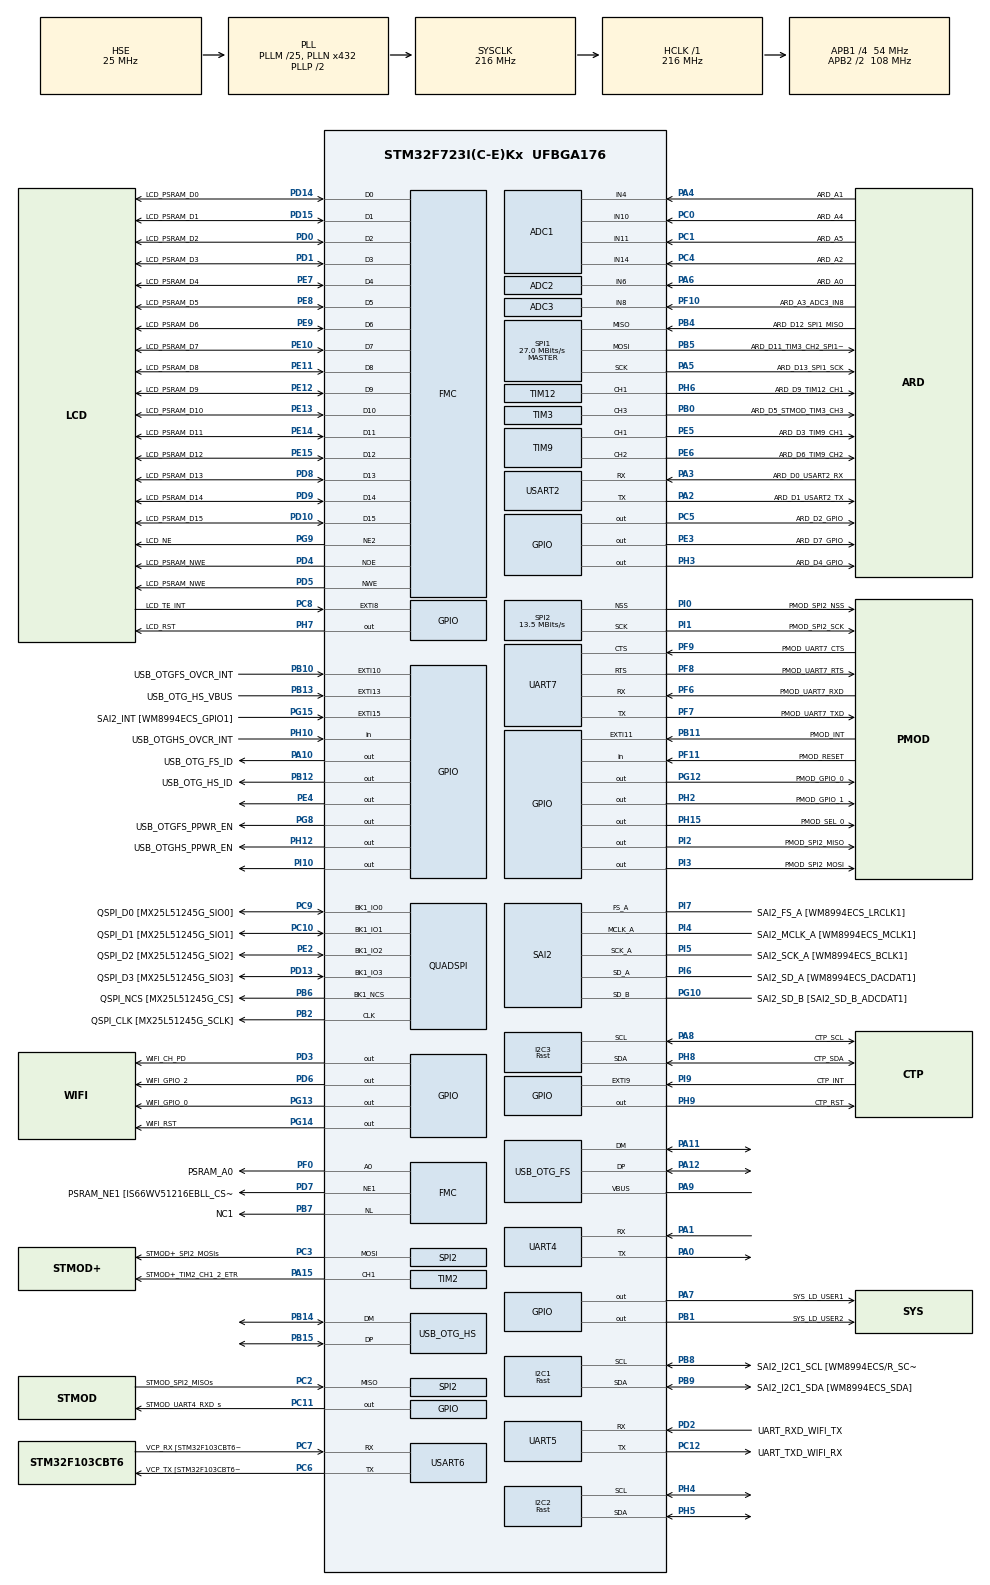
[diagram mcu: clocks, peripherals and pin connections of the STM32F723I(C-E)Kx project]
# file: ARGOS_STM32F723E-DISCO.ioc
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ADC1.Channel-0\#ChannelRegularConversion=ADC_CHANNEL_6
ADC1.Channel-11\#ChannelRegularConversion=ADC_CHANNEL_14
ADC1.Channel-8\#ChannelRegularConversion=ADC_CHANNEL_4
ADC1.ContinuousConvMode=ENABLE
ADC1.DiscontinuousConvMode=DISABLE
ADC1.EOCSelection=ADC_EOC_SINGLE_CONV
ADC1.ExternalTrigConv=ADC_SOFTWARE_START
ADC1.NbrOfConversion=3
ADC1.NbrOfConversionFlag=1
ADC1.Rank-0\#ChannelRegularConversion=1
ADC1.Rank-11\#ChannelRegularConversion=3
ADC1.Rank-8\#ChannelRegularConversion=2
ADC1.SamplingTime-0\#ChannelRegularConversion=ADC_SAMPLETIME_480CYCLES
ADC1.SamplingTime-11\#ChannelRegularConversion=ADC_SAMPLETIME_480CYCLES
ADC1.SamplingTime-8\#ChannelRegularConversion=ADC_SAMPLETIME_480CYCLES
ADC1.master=1
ADC2.Channel-25\#ChannelRegularConversion=ADC_CHANNEL_4
ADC2.NbrOfConversionFlag=1
ADC2.Rank-25\#ChannelRegularConversion=1
ADC2.SamplingTime-25\#ChannelRegularConversion=ADC_SAMPLETIME_3CYCLES
ADC3.Channel-0\#ChannelRegularConversion=ADC_CHANNEL_8
ADC3.NbrOfConversionFlag=1
ADC3.Rank-0\#ChannelRegularConversion=1
ADC3.SamplingTime-0\#ChannelRegularConversion=ADC_SAMPLETIME_3CYCLES
CORTEX_M7.CPU_ICache=Disabled
CORTEX_M7.PREFETCH_ENABLE=0
FMC.WriteOperation1=FMC_WRITE_OPERATION_ENABLE
I2C1.I2C_Speed_Mode=I2C_Fast
I2C1.Timing=0x6000030D
I2C2.I2C_Speed_Mode=I2C_Fast
I2C2.Timing=0x6000030D
I2C3.I2C_Speed_Mode=I2C_Fast
I2C3.Speed=400
I2C3.Timing=0x6000030D
Mcu.Family=STM32F7
Mcu.Name=STM32F723I(C-E)Kx
Mcu.Package=UFBGA176
NVIC.ADC_IRQn=true\:0\:0\:false\:false\:true\:true\:true\:true
NVIC.OTG_FS_IRQn=true\:0\:0\:false\:false\:true\:true\:true\:true
NVIC.OTG_HS_IRQn=true\:0\:0\:false\:false\:true\:true\:true\:true
NVIC.PriorityGroup=NVIC_PRIORITYGROUP_4
NVIC.TIM1_UP_TIM10_IRQn=true\:15\:0\:false\:false\:true\:true\:true\:true
NVIC.TIM5_IRQn=true\:0\:0\:false\:false\:true\:true\:true\:true
NVIC.TimeBase=TIM1_UP_TIM10_IRQn
NVIC.TimeBaseIP=TIM1
PA0-WKUP.GPIO_ModeDefaultPP=GPIO_MODE_AF_PP
PA0-WKUP.GPIO_PuPd=GPIO_NOPULL
PA0-WKUP.GPIO_Speed=GPIO_SPEED_FREQ_VERY_HIGH
PA0-WKUP.Mode=Asynchronous
PA0-WKUP.Signal=UART4_TX
PA1.Mode=Asynchronous
PA1.Signal=UART4_RX
PA10.GPIO_Label=USB_OTG_FS_ID
PA10.Signal=GPIO_Output
PA11.Mode=Host_Only
PA11.Signal=USB_OTG_FS_DM
PA12.Mode=Host_Only
PA12.Signal=USB_OTG_FS_DP
PA13.Mode=Trace_Asynchronous_SW
PA13.Signal=SYS_JTMS-SWDIO
PA14.Mode=Trace_Asynchronous_SW
PA14.Signal=SYS_JTCK-SWCLK
PA15.GPIO_Label=STMOD+_TIM2_CH1_2_ETR
PA15.Signal=S_TIM2_CH1_ETR
PA2.GPIO_Label=ARD_D1_USART2_TX
PA2.Mode=Asynchronous
PA2.Signal=USART2_TX
PA3.GPIO_Label=ARD_D0_USART2_RX
PA3.Mode=Asynchronous
PA3.Signal=USART2_RX
PA4.GPIO_Label=ARD_A1
PA4.Signal=ADCx_IN4
PA5.GPIO_Label=ARD_D13_SPI1_SCK
PA5.Mode=Full_Duplex_Master
PA5.Signal=SPI1_SCK
PA6.GPIO_Label=ARD_A0
PA6.Signal=ADCx_IN6
PA7.GPIO_Label=SYS_LD_USER1
PA7.Signal=GPIO_Output
PA8.GPIO_Label=CTP_SCL
PA8.GPIO_Pu=GPIO_PULLUP
PA8.Mode=I2C
PA8.Signal=I2C3_SCL
PA9.Mode=Activate_VBUS
PA9.Signal=USB_OTG_FS_VBUS
PB0.GPIO_Label=ARD_D5_STMOD_TIM3_CH3
PB0.Signal=S_TIM3_CH3
PB1.GPIO_Label=SYS_LD_USER2
PB1.Signal=GPIO_Output
PB10.GPIO_Label=USB_OTGFS_OVCR_INT
PB10.Signal=GPXTI10
PB11.GPIO_Label=PMOD_INT
PB11.Signal=GPXTI11
PB12.GPIO_Label=USB_OTG_HS_ID
PB12.Signal=GPIO_Output
PB13.GPIO_Label=USB_OTG_HS_VBUS
PB13.Signal=GPXTI13
PB14.Mode=Internal_Phy_Host
PB14.Signal=USB_OTG_HS_DM
PB15.Mode=Internal_Phy_Host
PB15.Signal=USB_OTG_HS_DP
PB2.GPIO_Label=QSPI_CLK [MX25L51245G_SCLK]
PB2.Mode=Single Bank 1
PB2.Signal=QUADSPI_CLK
PB3.GPIO_Label=SYS_STLINK_JTDO_SWO
PB3.Mode=Trace_Asynchronous_SW
PB3.Signal=SYS_JTDO-SWO
PB4.GPIO_Label=ARD_D12_SPI1_MISO
PB4.Mode=Full_Duplex_Master
PB4.Signal=SPI1_MISO
PB5.GPIO_Label=ARD_D11_TIM3_CH2_SPI1_MOSI
PB5.Mode=Full_Duplex_Master
PB5.Signal=SPI1_MOSI
PB6.GPIO_Label=QSPI_NCS [MX25L51245G_CS]
PB6.Mode=Single Bank 1
PB6.Signal=QUADSPI_BK1_NCS
PB7.GPIO_Label=NC1
PB7.Signal=FMC_NL
PB8.GPIO_Label=SAI2_I2C1_SCL [WM8994ECS/R_SCLK]
PB8.GPIO_Pu=GPIO_PULLUP
PB8.Mode=I2C
PB8.Signal=I2C1_SCL
PB9.GPIO_Label=SAI2_I2C1_SDA [WM8994ECS_SDA]
PB9.GPIO_Pu=GPIO_PULLUP
PB9.Mode=I2C
PB9.Signal=I2C1_SDA
PC0.GPIO_Label=ARD_A4
PC0.Signal=ADCx_IN10
PC1.GPIO_Label=ARD_A5
PC1.Signal=ADCx_IN11
PC10.GPIO_Label=QSPI_D1 [MX25L51245G_SIO1]
PC10.Mode=Single Bank 1
PC10.Signal=QUADSPI_BK1_IO1
PC11.GPIO_Label=STMOD_UART4_RXD_s
PC11.Signal=GPIO_Output
PC12.GPIO_Label=UART_TXD_WIFI_RX
PC12.Mode=Asynchronous
PC12.Signal=UART5_TX
PC14-OSC32_IN.Mode=LSE-External-Oscillator
PC14-OSC32_IN.Signal=RCC_OSC32_IN
PC15-OSC32_OUT.Mode=LSE-External-Oscillator
PC15-OSC32_OUT.Signal=RCC_OSC32_OUT
PC2.GPIO_Label=STMOD_SPI2_MISOs
PC2.Mode=Full_Duplex_Master
PC2.Signal=SPI2_MISO
PC3.GPIO_Label=STMOD+_SPI2_MOSIs
PC3.Mode=Full_Duplex_Master
PC3.Signal=SPI2_MOSI
PC4.GPIO_Label=ARD_A2
PC4.Signal=ADCx_IN14
PC5.GPIO_Label=ARD_D2_GPIO
PC5.Signal=GPIO_Output
PC6.GPIO_Label=VCP_TX [STM32F103CBT6_PA3]
PC6.Mode=Asynchronous
PC6.Signal=USART6_TX
PC7.GPIO_Label=VCP_RX [STM32F103CBT6_PA2]
PC7.Mode=Asynchronous
PC7.Signal=USART6_RX
PC8.GPIO_Label=LCD_TE_INT
PC8.Signal=GPXTI8
PC9.GPIO_Label=QSPI_D0 [MX25L51245G_SIO0]
PC9.Mode=Single Bank 1
PC9.Signal=QUADSPI_BK1_IO0
PD0.GPIO_Label=LCD_PSRAM_D2
PD0.Signal=FMC_D2_DA2
PD1.GPIO_Label=LCD_PSRAM_D3
PD1.Signal=FMC_D3_DA3
PD10.GPIO_Label=LCD_PSRAM_D15
PD10.Signal=FMC_D15_DA15
PD11.GPIO_Label=PSRAM_A16
PD11.Signal=FMC_A16_CLE
PD12.GPIO_Label=PSRAM_A17
PD12.Signal=FMC_A17_ALE
PD13.GPIO_Label=QSPI_D3 [MX25L51245G_SIO3]
PD13.Mode=Single Bank 1
PD13.Signal=QUADSPI_BK1_IO3
PD14.GPIO_Label=LCD_PSRAM_D0
PD14.Signal=FMC_D0_DA0
PD15.GPIO_Label=LCD_PSRAM_D1
PD15.Signal=FMC_D1_DA1
PD2.GPIO_Label=UART_RXD_WIFI_TX
PD2.Mode=Asynchronous
PD2.Signal=UART5_RX
PD3.GPIO_Label=WIFI_CH_PD
PD3.Signal=GPIO_Output
PD4.GPIO_Label=LCD_PSRAM_NWE
PD4.Signal=FMC_NOE
PD5.GPIO_Label=LCD_PSRAM_NWE
PD5.Signal=FMC_NWE
PD6.GPIO_Label=WIFI_GPIO_2
PD6.Signal=GPIO_Output
PD7.GPIO_Label=PSRAM_NE1 [IS66WV51216EBLL_CS1]
PD7.Mode=NorPsramChipSelect1_1
PD7.Signal=FMC_NE1
PD8.GPIO_Label=LCD_PSRAM_D13
PD8.Signal=FMC_D13_DA13
PD9.GPIO_Label=LCD_PSRAM_D14
PD9.Signal=FMC_D14_DA14
PE0.GPIO_Label=PSRAM_NBL0 [IS66WV51216EBLL_LB]
PE0.Signal=FMC_NBL0
PE1.GPIO_Label=PSRAM_NBL1 [IS66WV51216EBLL_UB]
PE1.Signal=FMC_NBL1
PE10.GPIO_Label=LCD_PSRAM_D7
PE10.Signal=FMC_D7_DA7
PE11.GPIO_Label=LCD_PSRAM_D8
PE11.Signal=FMC_D8_DA8
PE12.GPIO_Label=LCD_PSRAM_D9
PE12.Signal=FMC_D9_DA9
PE13.GPIO_Label=LCD_PSRAM_D10
PE13.Signal=FMC_D10_DA10
PE14.GPIO_Label=LCD_PSRAM_D11
PE14.Signal=FMC_D11_DA11
PE15.GPIO_Label=LCD_PSRAM_D12
PE15.Signal=FMC_D12_DA12
PE2.GPIO_Label=QSPI_D2 [MX25L51245G_SIO2]
PE2.Mode=Single Bank 1
PE2.Signal=QUADSPI_BK1_IO2
PE3.GPIO_Label=ARD_D7_GPIO
PE3.Signal=GPIO_Output
PE4.Signal=GPIO_Output
PE5.GPIO_Label=ARD_D3_TIM9_CH1
PE5.Signal=S_TIM9_CH1
PE6.GPIO_Label=ARD_D6_TIM9_CH2
PE6.Signal=S_TIM9_CH2
PE7.GPIO_Label=LCD_PSRAM_D4
PE7.Signal=FMC_D4_DA4
PE8.GPIO_Label=LCD_PSRAM_D5
PE8.Signal=FMC_D5_DA5
PE9.GPIO_Label=LCD_PSRAM_D6
PE9.Signal=FMC_D6_DA6
PF0.GPIO_Label=PSRAM_A0
PF0.Signal=FMC_A0
PF10.GPIO_Label=ARD_A3_ADC3_IN8
PF10.Mode=IN8
PF10.Signal=ADC3_IN8
PF11.GPIO_Label=PMOD_RESET
PF11.Signal=GPIO_Input
PF12.GPIO_Label=PSRAM_A6
PF12.Signal=FMC_A6
PF13.GPIO_Label=PSRAM_A7
PF13.Signal=FMC_A7
PF14.GPIO_Label=PSRAM_A8
PF14.Signal=FMC_A8
PF15.GPIO_Label=PSRAM_A9
PF15.Signal=FMC_A9
PF2.GPIO_Label=PSRAM_A2
PF2.Signal=FMC_A2
PF3.GPIO_Label=PSRAM_A3
PF3.Signal=FMC_A3
PF4.GPIO_Label=PSRAM_A4
PF4.Signal=FMC_A4
PF5.GPIO_Label=PSRAM_A5
PF5.Signal=FMC_A5
PF6.GPIO_Label=PMOD_UART7_RXD
PF6.Mode=Asynchronous
PF6.Signal=UART7_RX
PF7.GPIO_Label=PMOD_UART7_TXD
PF7.Mode=Asynchronous
PF7.Signal=UART7_TX
PF8.GPIO_Label=PMOD_UART7_RTS
PF8.Mode=CTS_RTS
PF8.Signal=UART7_RTS
PF9.GPIO_Label=PMOD_UART7_CTS
PF9.Mode=CTS_RTS
PF9.Signal=UART7_CTS
PG0.GPIO_Label=PSRAM_A10
PG0.Signal=FMC_A10
PG1.GPIO_Label=PSRAM_A11
PG1.Signal=FMC_A11
PG10.GPIO_Label=SAI2_SD_B [SAI2_SD_B_ADCDAT1]
PG10.Mode=SAI_B_SyncSlave
PG10.Signal=SAI2_SD_B
PG12.GPIO_Label=PMOD_GPIO_0
PG12.Signal=GPIO_Output
PG13.GPIO_Label=WIFI_GPIO_0
PG13.Signal=GPIO_Output
PG14.GPIO_Label=WIFI_RST
PG14.Signal=GPIO_Output
PG15.GPIO_Label=SAI2_INT [WM8994ECS_GPIO1]
PG15.Signal=GPXTI15
PG2.GPIO_Label=PSRAM_A12
PG2.Signal=FMC_A12
PG3.GPIO_Label=PSRAM_A13
PG3.Signal=FMC_A13
PG4.GPIO_Label=PSRAM_A14
PG4.Signal=FMC_A14_BA0
PG5.GPIO_Label=PSRAM_A15
PG5.Signal=FMC_A15_BA1
PG8.GPIO_Label=USB_OTGFS_PPWR_EN
PG8.Signal=GPIO_Output
PG9.GPIO_Label=LCD_NE
PG9.Mode=NorPsramChipSelect2_2
PG9.Signal=FMC_NE2
PH0-OSC_IN.Mode=HSE-External-Oscillator
PH0-OSC_IN.Signal=RCC_OSC_IN
PH1-OSC_OUT.Mode=HSE-External-Oscillator
PH1-OSC_OUT.Signal=RCC_OSC_OUT
PH10.GPIO_Label=USB_OTGHS_OVCR_INT
PH10.Signal=GPIO_Input
PH11.GPIO_Label=LCD_BL [STLD40DPUR_EN]
PH11.Signal=S_TIM5_CH2
PH12.GPIO_Label=USB_OTGHS_PPWR_EN
PH12.Signal=GPIO_Output
PH15.GPIO_Label=PMOD_SEL_0
PH15.PinState=GPIO_PIN_SET
PH15.Signal=GPIO_Output
PH2.GPIO_Label=PMOD_GPIO_1
PH2.Signal=GPIO_Output
PH3.GPIO_Label=ARD_D4_GPIO
PH3.Signal=GPIO_Output
PH4.Mode=I2C
PH4.Signal=I2C2_SCL
PH5.Mode=I2C
PH5.Signal=I2C2_SDA
PH6.GPIO_Label=ARD_D9_TIM12_CH1
PH6.Signal=S_TIM12_CH1
PH7.GPIO_Label=LCD_RST
PH7.Signal=GPIO_Output
PH8.GPIO_Label=CTP_SDA
PH8.GPIO_Pu=GPIO_PULLUP
PH8.Mode=I2C
PH8.Signal=I2C3_SDA
PH9.GPIO_Label=CTP_RST
PH9.Signal=GPIO_Output
PI0.GPIO_Label=PMOD_SPI2_NSS
PI0.Mode=NSS_Signal_Hard_Output
PI0.Signal=SPI2_NSS
PI1.GPIO_Label=PMOD_SPI2_SCK
PI1.Mode=Full_Duplex_Master
PI1.Signal=SPI2_SCK
PI10.Signal=GPIO_Output
PI2.GPIO_Label=PMOD_SPI2_MISO
PI2.Signal=GPIO_Output
PI3.GPIO_Label=PMOD_SPI2_MOSI
PI3.Signal=GPIO_Output
PI4.GPIO_Label=SAI2_MCLK_A [WM8994ECS_MCLK1]
PI4.Mode=SAI_A_MasterWithClock
PI4.Signal=SAI2_MCLK_A
PI5.GPIO_Label=SAI2_SCK_A [WM8994ECS_BCLK1]
PI5.Mode=SAI_A_MasterWithClock
PI5.Signal=SAI2_SCK_A
PI6.GPIO_Label=SAI2_SD_A [WM8994ECS_DACDAT1]
PI6.Mode=SAI_A_MasterWithClock
PI6.Signal=SAI2_SD_A
PI7.GPIO_Label=SAI2_FS_A [WM8994ECS_LRCLK1]
PI7.Mode=SAI_A_MasterWithClock
PI7.Signal=SAI2_FS_A
PI9.GPIO_Label=CTP_INT
PI9.Signal=GPXTI9
ProjectManager.HeapSize=0x200
ProjectManager.StackSize=0x400
ProjectManager.TargetToolchain=Makefile
QUADSPI.ChipSelectHighTime=QSPI_CS_HIGH_TIME_4_CYCLE
QUADSPI.ClockPrescaler=1
QUADSPI.FifoThreshold=16
QUADSPI.FlashSize=26
QUADSPI.SampleShifting=QSPI_SAMPLE_SHIFTING_HALFCYCLE
RCC.AHBFreq_Value=216000000
RCC.APB1CLKDivider=RCC_HCLK_DIV4
RCC.APB1Freq_Value=54000000
RCC.APB1TimFreq_Value=108000000
RCC.APB2CLKDivider=RCC_HCLK_DIV2
RCC.APB2Freq_Value=108000000
RCC.APB2TimFreq_Value=216000000
RCC.CortexFreq_Value=216000000
RCC.HCLKFreq_Value=216000000
RCC.HSE_VALUE=25000000
RCC.HSI_VALUE=16000000
RCC.PLLM=25
RCC.PLLN=432
RCC.PLLQ=9
RCC.SYSCLKFreq_VALUE=216000000
RCC.SYSCLKSource=RCC_SYSCLKSOURCE_PLLCLK
RCC.USBFreq_Value=48000000
RCC.VCOOutputFreq_Value=432000000
REXTPHYHS.GPIO_Label=REXT_OTGPHY
REXTPHYHS.Mode=Internal_Phy_Host
REXTPHYHS.Signal=USB_OTG_HS_REXTPHYHS
SAI2.ErrorAudioFreq-SAI_A_MasterWithClock=-2.34 %
SAI2.Instance-SAI_A_MasterWithClock=SAI$Index_Block_A
SAI2.Instance-SAI_B_SyncSlave=SAI$Index_Block_B
SAI2.MClockEnable-SAI_A_MasterWithClock=SAI_MASTERCLOCK_ENABLE
SAI2.RealAudioFreq-SAI_A_MasterWithClock=187.5 KHz
SAI2.VirtualMode-SAI_A_MasterWithClock=VM_MASTER
SAI2.VirtualMode-SAI_B_SyncSlave=VM_SLAVE
SH.ADCx_IN10.0=ADC1_IN10,IN10
SH.ADCx_IN10.1=ADC2_IN10,IN10
SH.ADCx_IN11.0=ADC1_IN11,IN11
SH.ADCx_IN11.1=ADC2_IN11,IN11
SH.ADCx_IN14.0=ADC1_IN14,IN14
SH.ADCx_IN14.1=ADC2_IN14,IN14
SH.ADCx_IN4.0=ADC1_IN4,IN4
SH.ADCx_IN4.1=ADC2_IN4,IN4
SH.ADCx_IN6.0=ADC2_IN6,IN6
SH.ADCx_IN6.1=ADC1_IN6,IN6
SH.FMC_A0.0=FMC_A0,A0_2
SH.FMC_A10.0=FMC_A10
SH.FMC_A11.0=FMC_A11
SH.FMC_A12.0=FMC_A12
SH.FMC_A13.0=FMC_A13
SH.FMC_A14_BA0.0=FMC_A14
SH.FMC_A15_BA1.0=FMC_A15
SH.FMC_A16_CLE.0=FMC_A16
SH.FMC_A17_ALE.0=FMC_A17
SH.FMC_A2.0=FMC_A2
SH.FMC_A3.0=FMC_A3
SH.FMC_A4.0=FMC_A4
SH.FMC_A5.0=FMC_A5
SH.FMC_A6.0=FMC_A6
SH.FMC_A7.0=FMC_A7
SH.FMC_A8.0=FMC_A8
SH.FMC_A9.0=FMC_A9
SH.FMC_D0_DA0.0=FMC_D0,16b-d2
SH.FMC_D10_DA10.0=FMC_D10,16b-d2
SH.FMC_D11_DA11.0=FMC_D11,16b-d2
SH.FMC_D12_DA12.0=FMC_D12,16b-d2
SH.FMC_D13_DA13.0=FMC_D13,16b-d2
SH.FMC_D14_DA14.0=FMC_D14,16b-d2
SH.FMC_D15_DA15.0=FMC_D15,16b-d2
SH.FMC_D1_DA1.0=FMC_D1,16b-d2
SH.FMC_D2_DA2.0=FMC_D2,16b-d2
SH.FMC_D3_DA3.0=FMC_D3,16b-d2
SH.FMC_D4_DA4.0=FMC_D4,16b-d2
SH.FMC_D5_DA5.0=FMC_D5,16b-d2
SH.FMC_D6_DA6.0=FMC_D6,16b-d2
SH.FMC_D7_DA7.0=FMC_D7,16b-d2
SH.FMC_D8_DA8.0=FMC_D8,16b-d2
SH.FMC_D9_DA9.0=FMC_D9,16b-d2
SH.FMC_NBL0.0=FMC_NBL0
SH.FMC_NBL1.0=FMC_NBL1
SH.FMC_NL.0=FMC_NL,AddressValid1
SH.FMC_NOE.0=FMC_NOE,Psram1
SH.FMC_NOE.1=FMC_NOE,Lcd2
SH.FMC_NWE.0=FMC_NWE,Psram1
SH.FMC_NWE.1=FMC_NWE,Lcd2
SH.S_TIM12_CH1.0=TIM12_CH1,PWM Generation1 CH1
SH.S_TIM2_CH1_ETR.0=TIM2_CH1,PWM Generation1 CH1
SH.S_TIM3_CH3.0=TIM3_CH3,PWM Generation3 CH3
SH.S_TIM5_CH2.0=TIM5_CH2
SH.S_TIM9_CH1.0=TIM9_CH1,PWM Generation1 CH1
SH.S_TIM9_CH2.0=TIM9_CH2,PWM Generation2 CH2
SPI1.BaudRatePrescaler=SPI_BAUDRATEPRESCALER_4
SPI1.CalculateBaudRate=27.0 MBits/s
SPI1.Direction=SPI_DIRECTION_2LINES
SPI1.Mode=SPI_MODE_MASTER
SPI1.VirtualType=VM_MASTER
SPI2.BaudRatePrescaler=SPI_BAUDRATEPRESCALER_4
SPI2.CalculateBaudRate=13.5 MBits/s
SPI2.Direction=SPI_DIRECTION_2LINES
SPI2.Mode=SPI_MODE_MASTER
SPI2.VirtualNSS=VM_NSSHARD
SPI2.VirtualType=VM_MASTER
TIM12.Channel-PWM\ Generation1\ CH1=TIM_CHANNEL_1
TIM2.Channel-PWM\ Generation1\ CH1=TIM_CHANNEL_1
TIM2.Channel-PWM\ Generation2\ CH2=TIM_CHANNEL_2
TIM3.Channel-PWM\ Generation3\ CH3=TIM_CHANNEL_3
TIM5.Period=216000
TIM5.TIM_MasterOutputTrigger=TIM_TRGO_UPDATE
TIM9.Channel-PWM\ Generation1\ CH1=TIM_CHANNEL_1
TIM9.Channel-PWM\ Generation2\ CH2=TIM_CHANNEL_2
USART2.VirtualMode-Asynchronous=VM_ASYNC
USART6.VirtualMode-Asynchronous=VM_ASYNC
USB_HOST.BSP.number=2
USB_HOST.USBH_HandleTypeDef-AUDIO_HS=hUsbHostHS
USB_HOST.USBH_HandleTypeDef-MSC_FS=hUsbHostFS
USB_HOST.VirtualModeFS=Msc
USB_HOST.VirtualModeHS=Audio
USB_HOST0.BSP.STBoard=false
USB_HOST0.BSP.api=Unknown
USB_HOST0.BSP.instance=PG8
USB_HOST0.BSP.ip=GPIO
USB_HOST0.BSP.mode=Output
USB_HOST0.BSP.name=Drive_VBUS_FS
USB_HOST0.BSP.solution=PG8
USB_HOST1.BSP.STBoard=false
USB_HOST1.BSP.api=Unknown
USB_HOST1.BSP.instance=PH12
USB_HOST1.BSP.ip=GPIO
USB_HOST1.BSP.mode=Output
USB_HOST1.BSP.name=Drive_VBUS_HS
USB_HOST1.BSP.solution=PH12
USB_OTG_FS.VirtualMode=Host_Only
USB_OTG_FS.phy_itface=HCD_PHY_EMBEDDED
USB_OTG_HS.VirtualMode=Int_Phy_Host
VP_SYS_VS_tim1.Mode=TIM1
VP_TIM5_VS_ClockSourceINT.Mode=Internal
VP_USB_HOST_VS_USB_HOST_AUDIO_HS.Mode=AUDIO_HS
VP_USB_HOST_VS_USB_HOST_MSC_FS.Mode=MSC_FS
board=STM32F723E-DISCO

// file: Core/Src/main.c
/* USER CODE BEGIN Header */
/**
  ******************************************************************************
  * @file           : main.c
  * @brief          : Main program body
  ******************************************************************************
  * @attention
  *
  * Copyright (c) 2024 STMicroelectronics.
  * All rights reserved.
  *
  * This software is licensed under terms that can be found in the LICENSE file
  * in the root directory of this software component.
  * If no LICENSE file comes with this software, it is provided AS-IS.
  *
  ******************************************************************************
  */
/* USER CODE END Header */
#include "main.h"
#include "usb_host.h"

/* USER CODE BEGIN Includes */
#include "pca9685.h"
#include "motor.h"
#include "leg.h"
#include "quadruped.h"
#include "stdlib.h"
#include <stdio.h>
#include "string.h"
#include "input_functions.h"
#include "argos_parameters.h"

/* USER CODE END Includes */

ADC_HandleTypeDef hadc1;
ADC_HandleTypeDef hadc2;
ADC_HandleTypeDef hadc3;

I2C_HandleTypeDef hi2c1;
I2C_HandleTypeDef hi2c2;
I2C_HandleTypeDef hi2c3;

QSPI_HandleTypeDef hqspi;

SAI_HandleTypeDef hsai_BlockA2;
SAI_HandleTypeDef hsai_BlockB2;

SPI_HandleTypeDef hspi1;
SPI_HandleTypeDef hspi2;

TIM_HandleTypeDef htim2;
TIM_HandleTypeDef htim3;
TIM_HandleTypeDef htim5;
TIM_HandleTypeDef htim9;
TIM_HandleTypeDef htim12;

UART_HandleTypeDef huart4;
UART_HandleTypeDef huart5;
UART_HandleTypeDef huart7;
UART_HandleTypeDef huart2;
UART_HandleTypeDef huart6;

SRAM_HandleTypeDef hsram1;
SRAM_HandleTypeDef hsram2;

/* USER CODE BEGIN PV */

//Motor Set:

//Motor Definitions

//Leg1
  motor_t motor1 = {
    .motorPin = 0,
  };

  motor_t motor2 = {
    .motorPin = 1,
  };

  motor_t motor3 = {
    .motorPin = 2,
    };

//Leg2
  motor_t motor4 = {
    .motorPin = 3,
  };

  motor_t motor5 = {
    .motorPin = 4,
  };

  motor_t motor6 = {
    .motorPin = 5,
  };

//Leg3
   motor_t motor7 = {
    .motorPin = 6,
  };

  motor_t motor8 = {
    .motorPin = 7,
  };

  motor_t motor9 = {
    .motorPin = 8,
  };

//Leg3
  motor_t motor10 = {
  .motorPin = 9,
  };

  motor_t motor11 = {
    .motorPin = 10,
  };

  motor_t motor12 = {
    .motorPin = 11,
  };

//Leg Definitions
leg_t leg1 = {
  .motorList = {&motor1, &motor2, &motor3},
  .reflectionMap = {0, 0, 1, 1, 1, 1},
  .d_torso_foot = {xf1, yf, zf},
  .d_torso_hip = {L1, -height, width}
};

leg_t leg2 = {
  .motorList = {&motor4, &motor5, &motor6},
  .reflectionMap = {1,1 , 0, 1, -1, -1},
  .d_torso_foot = {xf1, yf, -zf},
  .d_torso_hip = {L1, -height, -width}
};

leg_t leg3 = {
  .motorList = {&motor7, &motor8, &motor9},
  .reflectionMap = {1, 0, 1, -1, 1, 1},
  .d_torso_foot = {-xf2, yf, zf},
  .d_torso_hip = {-L2, -height, width}
};

leg_t leg4 = {
  .motorList = {&motor10, &motor11, &motor12},
  .reflectionMap = {0, 1, 0, -1, -1, -1},
  .d_torso_foot = {-xf2, yf, -zf},
  .d_torso_hip = {-L2, -height, -width}
};

//Quadruped Definition
quadruped_t argos = {
  .legList = {&leg1, &leg2, &leg3, &leg4}
};

/* USER CODE END PV */

void SystemClock_Config(void);
void PeriphCommonClock_Config(void);
static void MX_GPIO_Init(void);
static void MX_ADC1_Init(void);
static void MX_ADC2_Init(void);
static void MX_ADC3_Init(void);
static void MX_FMC_Init(void);
static void MX_I2C1_Init(void);
static void MX_I2C2_Init(void);
static void MX_I2C3_Init(void);
static void MX_QUADSPI_Init(void);
static void MX_SAI2_Init(void);
static void MX_SPI1_Init(void);
static void MX_SPI2_Init(void);
static void MX_TIM2_Init(void);
static void MX_TIM3_Init(void);
static void MX_TIM5_Init(void);
static void MX_TIM9_Init(void);
static void MX_TIM12_Init(void);
static void MX_UART4_Init(void);
static void MX_UART5_Init(void);
static void MX_UART7_Init(void);
static void MX_USART2_UART_Init(void);
static void MX_USART6_UART_Init(void);
void MX_USB_HOST_Process(void);

int main(void)

   {

  /* MCU Configuration--------------------------------------------------------*/

  /* Reset of all peripherals, Initializes the Flash interface and the Systick. */
  HAL_Init();

  /* Configure the system clock */
  SystemClock_Config();

  /* Configure the peripherals common clocks */
  PeriphCommonClock_Config();

  /* Initialize all configured peripherals */
  MX_GPIO_Init();
  MX_ADC1_Init();
  MX_ADC2_Init();
  MX_ADC3_Init();
  MX_FMC_Init();
  MX_I2C1_Init();
  MX_I2C2_Init();
  MX_I2C3_Init();
  MX_QUADSPI_Init();
  MX_SAI2_Init();
  MX_SPI1_Init();
  MX_SPI2_Init();
  MX_TIM2_Init();
  MX_TIM3_Init();
  MX_TIM5_Init();
  MX_TIM9_Init();
  MX_TIM12_Init();
  MX_UART4_Init();
  MX_UART5_Init();
  MX_UART7_Init();
  MX_USART2_UART_Init();
  MX_USART6_UART_Init();
  MX_USB_HOST_Init();
  /* USER CODE BEGIN 2 */

  HAL_ADC_Start(&hadc1);

  //Quad inits
  PCA9685_Init();
  PCA9685_SetPWMFrequency(50);
  quadHome(&argos);

  //PRINT STATEMENTS
  //ADC Data Array Declarations
  uint16_t adcValues_raw[3];
  float adcValues_clipped[3];

  float dx;
  float dy;
  float dz;

  //Serial Buffer
  char messageBuffer[100];

  /* USER CODE END 2 */

  /* Infinite loop */
  /* USER CODE BEGIN WHILE */
  while (1)
  {

  //Recieve Data
      HAL_ADC_Start(&hadc1);
    for (int i = 0; i < 3 ; i++){
      if (HAL_ADC_PollForConversion(&hadc1, 100) == HAL_OK){
        adcValues_raw[i] = HAL_ADC_GetValue(&hadc1);
      }
    }
  HAL_ADC_Stop(&hadc1);

  //Clip/Scale
    analogClipSet(adcValues_raw, adcValues_clipped, 50, 3,3.0);

  //Testing Values
    dx = adcValues_clipped[0];
    dy = adcValues_clipped[1];
    dz = adcValues_clipped[2];

  //Demo Walk Cycle
  quadWalk(&argos, 0.5);

  // // Serial Print dx /dy /dz
  sprintf(messageBuffer, "dx = %.2f          dy = %.2f       dz = %.2f  \n\r", dx, dy, dz);
  HAL_UART_Transmit(&huart6,  (const uint8_t*)messageBuffer, strlen(messageBuffer), 10);

}
    /* USER CODE END WHILE */
    MX_USB_HOST_Process();

}

void SystemClock_Config(void)
{
  RCC_OscInitTypeDef RCC_OscInitStruct = {0};
  RCC_ClkInitTypeDef RCC_ClkInitStruct = {0};

  /** Configure LSE Drive Capability
  */
  HAL_PWR_EnableBkUpAccess();

  /** Configure the main internal regulator output voltage
  */
  __HAL_RCC_PWR_CLK_ENABLE();
  __HAL_PWR_VOLTAGESCALING_CONFIG(PWR_REGULATOR_VOLTAGE_SCALE1);

  /** Initializes the RCC Oscillators according to the specified parameters
  * in the RCC_OscInitTypeDef structure.
  */
  RCC_OscInitStruct.OscillatorType = RCC_OSCILLATORTYPE_HSE;
  RCC_OscInitStruct.HSEState = RCC_HSE_ON;
  RCC_OscInitStruct.PLL.PLLState = RCC_PLL_ON;
  RCC_OscInitStruct.PLL.PLLSource = RCC_PLLSOURCE_HSE;
  RCC_OscInitStruct.PLL.PLLM = 25;
  RCC_OscInitStruct.PLL.PLLN = 432;
  RCC_OscInitStruct.PLL.PLLP = RCC_PLLP_DIV2;
  RCC_OscInitStruct.PLL.PLLQ = 9;
  if (HAL_RCC_OscConfig(&RCC_OscInitStruct) != HAL_OK)
  {
    Error_Handler();
  }

  /** Activate the Over-Drive mode
  */
  if (HAL_PWREx_EnableOverDrive() != HAL_OK)
  {
    Error_Handler();
  }

  /** Initializes the CPU, AHB and APB buses clocks
  */
  RCC_ClkInitStruct.ClockType = RCC_CLOCKTYPE_HCLK|RCC_CLOCKTYPE_SYSCLK
                              |RCC_CLOCKTYPE_PCLK1|RCC_CLOCKTYPE_PCLK2;
  RCC_ClkInitStruct.SYSCLKSource = RCC_SYSCLKSOURCE_PLLCLK;
  RCC_ClkInitStruct.AHBCLKDivider = RCC_SYSCLK_DIV1;
  RCC_ClkInitStruct.APB1CLKDivider = RCC_HCLK_DIV4;
  RCC_ClkInitStruct.APB2CLKDivider = RCC_HCLK_DIV2;

  if (HAL_RCC_ClockConfig(&RCC_ClkInitStruct, FLASH_LATENCY_7) != HAL_OK)
  {
    Error_Handler();
  }
}

void PeriphCommonClock_Config(void)
{
  RCC_PeriphCLKInitTypeDef PeriphClkInitStruct = {0};

  /** Initializes the peripherals clock
  */
  PeriphClkInitStruct.PeriphClockSelection = RCC_PERIPHCLK_SAI2|RCC_PERIPHCLK_CLK48;
  PeriphClkInitStruct.PLLSAI.PLLSAIN = 192;
  PeriphClkInitStruct.PLLSAI.PLLSAIQ = 2;
  PeriphClkInitStruct.PLLSAI.PLLSAIP = RCC_PLLSAIP_DIV2;
  PeriphClkInitStruct.PLLSAIDivQ = 1;
  PeriphClkInitStruct.Sai2ClockSelection = RCC_SAI2CLKSOURCE_PLLSAI;
  if (HAL_RCCEx_PeriphCLKConfig(&PeriphClkInitStruct) != HAL_OK)
  {
    Error_Handler();
  }
}

static void MX_ADC1_Init(void)
{

  ADC_ChannelConfTypeDef sConfig = {0};

  /** Configure the global features of the ADC (Clock, Resolution, Data Alignment and number of conversion)
  */
  hadc1.Instance = ADC1;
  hadc1.Init.ClockPrescaler = ADC_CLOCK_SYNC_PCLK_DIV4;
  hadc1.Init.Resolution = ADC_RESOLUTION_12B;
  hadc1.Init.ScanConvMode = ADC_SCAN_ENABLE;
  hadc1.Init.ContinuousConvMode = ENABLE;
  hadc1.Init.DiscontinuousConvMode = DISABLE;
  hadc1.Init.ExternalTrigConvEdge = ADC_EXTERNALTRIGCONVEDGE_NONE;
  hadc1.Init.ExternalTrigConv = ADC_SOFTWARE_START;
  hadc1.Init.DataAlign = ADC_DATAALIGN_RIGHT;
  hadc1.Init.NbrOfConversion = 3;
  hadc1.Init.DMAContinuousRequests = DISABLE;
  hadc1.Init.EOCSelection = ADC_EOC_SINGLE_CONV;
  if (HAL_ADC_Init(&hadc1) != HAL_OK)
  {
    Error_Handler();
  }

  /** Configure for the selected ADC regular channel its corresponding rank in the sequencer and its sample time.
  */
  sConfig.Channel = ADC_CHANNEL_6;
  sConfig.Rank = ADC_REGULAR_RANK_1;
  sConfig.SamplingTime = ADC_SAMPLETIME_480CYCLES;
  if (HAL_ADC_ConfigChannel(&hadc1, &sConfig) != HAL_OK)
  {
    Error_Handler();
  }

  /** Configure for the selected ADC regular channel its corresponding rank in the sequencer and its sample time.
  */
  sConfig.Channel = ADC_CHANNEL_4;
  sConfig.Rank = ADC_REGULAR_RANK_2;
  if (HAL_ADC_ConfigChannel(&hadc1, &sConfig) != HAL_OK)
  {
    Error_Handler();
  }

  /** Configure for the selected ADC regular channel its corresponding rank in the sequencer and its sample time.
  */
  sConfig.Channel = ADC_CHANNEL_14;
  sConfig.Rank = ADC_REGULAR_RANK_3;
  if (HAL_ADC_ConfigChannel(&hadc1, &sConfig) != HAL_OK)
  {
    Error_Handler();
  }

}

static void MX_ADC2_Init(void)
{

  ADC_ChannelConfTypeDef sConfig = {0};

  /** Configure the global features of the ADC (Clock, Resolution, Data Alignment and number of conversion)
  */
  hadc2.Instance = ADC2;
  hadc2.Init.ClockPrescaler = ADC_CLOCK_SYNC_PCLK_DIV4;
  hadc2.Init.Resolution = ADC_RESOLUTION_12B;
  hadc2.Init.ScanConvMode = ADC_SCAN_DISABLE;
  hadc2.Init.ContinuousConvMode = DISABLE;
  hadc2.Init.DiscontinuousConvMode = DISABLE;
  hadc2.Init.ExternalTrigConvEdge = ADC_EXTERNALTRIGCONVEDGE_NONE;
  hadc2.Init.ExternalTrigConv = ADC_SOFTWARE_START;
  hadc2.Init.DataAlign = ADC_DATAALIGN_RIGHT;
  hadc2.Init.NbrOfConversion = 1;
  hadc2.Init.DMAContinuousRequests = DISABLE;
  hadc2.Init.EOCSelection = ADC_EOC_SINGLE_CONV;
  if (HAL_ADC_Init(&hadc2) != HAL_OK)
  {
    Error_Handler();
  }

  /** Configure for the selected ADC regular channel its corresponding rank in the sequencer and its sample time.
  */
  sConfig.Channel = ADC_CHANNEL_4;
  sConfig.Rank = ADC_REGULAR_RANK_1;
  sConfig.SamplingTime = ADC_SAMPLETIME_3CYCLES;
  if (HAL_ADC_ConfigChannel(&hadc2, &sConfig) != HAL_OK)
  {
    Error_Handler();
  }

}

static void MX_ADC3_Init(void)
{

  ADC_ChannelConfTypeDef sConfig = {0};

  /** Configure the global features of the ADC (Clock, Resolution, Data Alignment and number of conversion)
  */
  hadc3.Instance = ADC3;
  hadc3.Init.ClockPrescaler = ADC_CLOCK_SYNC_PCLK_DIV4;
  hadc3.Init.Resolution = ADC_RESOLUTION_12B;
  hadc3.Init.ScanConvMode = ADC_SCAN_DISABLE;
  hadc3.Init.ContinuousConvMode = DISABLE;
  hadc3.Init.DiscontinuousConvMode = DISABLE;
  hadc3.Init.ExternalTrigConvEdge = ADC_EXTERNALTRIGCONVEDGE_NONE;
  hadc3.Init.ExternalTrigConv = ADC_SOFTWARE_START;
  hadc3.Init.DataAlign = ADC_DATAALIGN_RIGHT;
  hadc3.Init.NbrOfConversion = 1;
  hadc3.Init.DMAContinuousRequests = DISABLE;
  hadc3.Init.EOCSelection = ADC_EOC_SINGLE_CONV;
  if (HAL_ADC_Init(&hadc3) != HAL_OK)
  {
    Error_Handler();
  }

  /** Configure for the selected ADC regular channel its corresponding rank in the sequencer and its sample time.
  */
  sConfig.Channel = ADC_CHANNEL_8;
  sConfig.Rank = ADC_REGULAR_RANK_1;
  sConfig.SamplingTime = ADC_SAMPLETIME_3CYCLES;
  if (HAL_ADC_ConfigChannel(&hadc3, &sConfig) != HAL_OK)
  {
    Error_Handler();
  }

}

static void MX_I2C1_Init(void)
{

  hi2c1.Instance = I2C1;
  hi2c1.Init.Timing = 0x6000030D;
  hi2c1.Init.OwnAddress1 = 0;
  hi2c1.Init.AddressingMode = I2C_ADDRESSINGMODE_7BIT;
  hi2c1.Init.DualAddressMode = I2C_DUALADDRESS_DISABLE;
  hi2c1.Init.OwnAddress2 = 0;
  hi2c1.Init.OwnAddress2Masks = I2C_OA2_NOMASK;
  hi2c1.Init.GeneralCallMode = I2C_GENERALCALL_DISABLE;
  hi2c1.Init.NoStretchMode = I2C_NOSTRETCH_DISABLE;
  if (HAL_I2C_Init(&hi2c1) != HAL_OK)
  {
    Error_Handler();
  }

  /** Configure Analogue filter
  */
  if (HAL_I2CEx_ConfigAnalogFilter(&hi2c1, I2C_ANALOGFILTER_ENABLE) != HAL_OK)
  {
    Error_Handler();
  }

  /** Configure Digital filter
  */
  if (HAL_I2CEx_ConfigDigitalFilter(&hi2c1, 0) != HAL_OK)
  {
    Error_Handler();
  }

}

static void MX_I2C2_Init(void)
{

  hi2c2.Instance = I2C2;
  hi2c2.Init.Timing = 0x6000030D;
  hi2c2.Init.OwnAddress1 = 0;
  hi2c2.Init.AddressingMode = I2C_ADDRESSINGMODE_7BIT;
  hi2c2.Init.DualAddressMode = I2C_DUALADDRESS_DISABLE;
  hi2c2.Init.OwnAddress2 = 0;
  hi2c2.Init.OwnAddress2Masks = I2C_OA2_NOMASK;
  hi2c2.Init.GeneralCallMode = I2C_GENERALCALL_DISABLE;
  hi2c2.Init.NoStretchMode = I2C_NOSTRETCH_DISABLE;
  if (HAL_I2C_Init(&hi2c2) != HAL_OK)
  {
    Error_Handler();
  }

  /** Configure Analogue filter
  */
  if (HAL_I2CEx_ConfigAnalogFilter(&hi2c2, I2C_ANALOGFILTER_ENABLE) != HAL_OK)
  {
    Error_Handler();
  }

  /** Configure Digital filter
  */
  if (HAL_I2CEx_ConfigDigitalFilter(&hi2c2, 0) != HAL_OK)
  {
    Error_Handler();
  }

}

static void MX_I2C3_Init(void)
{

  hi2c3.Instance = I2C3;
  hi2c3.Init.Timing = 0x6000030D;
  hi2c3.Init.OwnAddress1 = 0;
  hi2c3.Init.AddressingMode = I2C_ADDRESSINGMODE_7BIT;
  hi2c3.Init.DualAddressMode = I2C_DUALADDRESS_DISABLE;
  hi2c3.Init.OwnAddress2 = 0;
  hi2c3.Init.OwnAddress2Masks = I2C_OA2_NOMASK;
  hi2c3.Init.GeneralCallMode = I2C_GENERALCALL_DISABLE;
  hi2c3.Init.NoStretchMode = I2C_NOSTRETCH_DISABLE;
  if (HAL_I2C_Init(&hi2c3) != HAL_OK)
  {
    Error_Handler();
  }

  /** Configure Analogue filter
  */
  if (HAL_I2CEx_ConfigAnalogFilter(&hi2c3, I2C_ANALOGFILTER_ENABLE) != HAL_OK)
  {
    Error_Handler();
  }

  /** Configure Digital filter
  */
  if (HAL_I2CEx_ConfigDigitalFilter(&hi2c3, 0) != HAL_OK)
  {
    Error_Handler();
  }

}

static void MX_QUADSPI_Init(void)
{

  /* QUADSPI parameter configuration*/
  hqspi.Instance = QUADSPI;
  hqspi.Init.ClockPrescaler = 1;
  hqspi.Init.FifoThreshold = 16;
  hqspi.Init.SampleShifting = QSPI_SAMPLE_SHIFTING_HALFCYCLE;
  hqspi.Init.FlashSize = 26;
  hqspi.Init.ChipSelectHighTime = QSPI_CS_HIGH_TIME_4_CYCLE;
  hqspi.Init.ClockMode = QSPI_CLOCK_MODE_0;
  hqspi.Init.FlashID = QSPI_FLASH_ID_1;
  hqspi.Init.DualFlash = QSPI_DUALFLASH_DISABLE;
  if (HAL_QSPI_Init(&hqspi) != HAL_OK)
  {
    Error_Handler();
  }

}

static void MX_SAI2_Init(void)
{

  hsai_BlockA2.Instance = SAI2_Block_A;
  hsai_BlockA2.Init.Protocol = SAI_FREE_PROTOCOL;
  hsai_BlockA2.Init.AudioMode = SAI_MODEMASTER_TX;
  hsai_BlockA2.Init.DataSize = SAI_DATASIZE_8;
  hsai_BlockA2.Init.FirstBit = SAI_FIRSTBIT_MSB;
  hsai_BlockA2.Init.ClockStrobing = SAI_CLOCKSTROBING_FALLINGEDGE;
  hsai_BlockA2.Init.Synchro = SAI_ASYNCHRONOUS;
  hsai_BlockA2.Init.OutputDrive = SAI_OUTPUTDRIVE_DISABLE;
  hsai_BlockA2.Init.NoDivider = SAI_MASTERDIVIDER_ENABLE;
  hsai_BlockA2.Init.FIFOThreshold = SAI_FIFOTHRESHOLD_EMPTY;
  hsai_BlockA2.Init.AudioFrequency = SAI_AUDIO_FREQUENCY_192K;
  hsai_BlockA2.Init.SynchroExt = SAI_SYNCEXT_DISABLE;
  hsai_BlockA2.Init.MonoStereoMode = SAI_STEREOMODE;
  hsai_BlockA2.Init.CompandingMode = SAI_NOCOMPANDING;
  hsai_BlockA2.Init.TriState = SAI_OUTPUT_NOTRELEASED;
  hsai_BlockA2.FrameInit.FrameLength = 8;
  hsai_BlockA2.FrameInit.ActiveFrameLength = 1;
  hsai_BlockA2.FrameInit.FSDefinition = SAI_FS_STARTFRAME;
  hsai_BlockA2.FrameInit.FSPolarity = SAI_FS_ACTIVE_LOW;
  hsai_BlockA2.FrameInit.FSOffset = SAI_FS_FIRSTBIT;
  hsai_BlockA2.SlotInit.FirstBitOffset = 0;
  hsai_BlockA2.SlotInit.SlotSize = SAI_SLOTSIZE_DATASIZE;
  hsai_BlockA2.SlotInit.SlotNumber = 1;
  hsai_BlockA2.SlotInit.SlotActive = 0x00000000;
  if (HAL_SAI_Init(&hsai_BlockA2) != HAL_OK)
  {
    Error_Handler();
  }
  hsai_BlockB2.Instance = SAI2_Block_B;
  hsai_BlockB2.Init.Protocol = SAI_FREE_PROTOCOL;
  hsai_BlockB2.Init.AudioMode = SAI_MODESLAVE_RX;
  hsai_BlockB2.Init.DataSize = SAI_DATASIZE_8;
  hsai_BlockB2.Init.FirstBit = SAI_FIRSTBIT_MSB;
  hsai_BlockB2.Init.ClockStrobing = SAI_CLOCKSTROBING_FALLINGEDGE;
  hsai_BlockB2.Init.Synchro = SAI_SYNCHRONOUS;
  hsai_BlockB2.Init.OutputDrive = SAI_OUTPUTDRIVE_DISABLE;
  hsai_BlockB2.Init.FIFOThreshold = SAI_FIFOTHRESHOLD_EMPTY;
  hsai_BlockB2.Init.SynchroExt = SAI_SYNCEXT_DISABLE;
  hsai_BlockB2.Init.MonoStereoMode = SAI_STEREOMODE;
  hsai_BlockB2.Init.CompandingMode = SAI_NOCOMPANDING;
  hsai_BlockB2.Init.TriState = SAI_OUTPUT_NOTRELEASED;
  hsai_BlockB2.FrameInit.FrameLength = 8;
  hsai_BlockB2.FrameInit.ActiveFrameLength = 1;
  hsai_BlockB2.FrameInit.FSDefinition = SAI_FS_STARTFRAME;
  hsai_BlockB2.FrameInit.FSPolarity = SAI_FS_ACTIVE_LOW;
  hsai_BlockB2.FrameInit.FSOffset = SAI_FS_FIRSTBIT;
  hsai_BlockB2.SlotInit.FirstBitOffset = 0;
  hsai_BlockB2.SlotInit.SlotSize = SAI_SLOTSIZE_DATASIZE;
  hsai_BlockB2.SlotInit.SlotNumber = 1;
  hsai_BlockB2.SlotInit.SlotActive = 0x00000000;
  if (HAL_SAI_Init(&hsai_BlockB2) != HAL_OK)
  {
    Error_Handler();
  }

}

static void MX_SPI1_Init(void)
{

  /* SPI1 parameter configuration*/
  hspi1.Instance = SPI1;
  hspi1.Init.Mode = SPI_MODE_MASTER;
  hspi1.Init.Direction = SPI_DIRECTION_2LINES;
  hspi1.Init.DataSize = SPI_DATASIZE_4BIT;
  hspi1.Init.CLKPolarity = SPI_POLARITY_LOW;
  hspi1.Init.CLKPhase = SPI_PHASE_1EDGE;
  hspi1.Init.NSS = SPI_NSS_SOFT;
  hspi1.Init.BaudRatePrescaler = SPI_BAUDRATEPRESCALER_4;
  hspi1.Init.FirstBit = SPI_FIRSTBIT_MSB;
  hspi1.Init.TIMode = SPI_TIMODE_DISABLE;
  hspi1.Init.CRCCalculation = SPI_CRCCALCULATION_DISABLE;
  hspi1.Init.CRCPolynomial = 7;
  hspi1.Init.CRCLength = SPI_CRC_LENGTH_DATASIZE;
  hspi1.Init.NSSPMode = SPI_NSS_PULSE_ENABLE;
  if (HAL_SPI_Init(&hspi1) != HAL_OK)
  {
    Error_Handler();
  }

}

static void MX_SPI2_Init(void)
{

  /* SPI2 parameter configuration*/
  hspi2.Instance = SPI2;
  hspi2.Init.Mode = SPI_MODE_MASTER;
  hspi2.Init.Direction = SPI_DIRECTION_2LINES;
  hspi2.Init.DataSize = SPI_DATASIZE_4BIT;
  hspi2.Init.CLKPolarity = SPI_POLARITY_LOW;
  hspi2.Init.CLKPhase = SPI_PHASE_1EDGE;
  hspi2.Init.NSS = SPI_NSS_HARD_OUTPUT;
  hspi2.Init.BaudRatePrescaler = SPI_BAUDRATEPRESCALER_4;
  hspi2.Init.FirstBit = SPI_FIRSTBIT_MSB;
  hspi2.Init.TIMode = SPI_TIMODE_DISABLE;
  hspi2.Init.CRCCalculation = SPI_CRCCALCULATION_DISABLE;
  hspi2.Init.CRCPolynomial = 7;
  hspi2.Init.CRCLength = SPI_CRC_LENGTH_DATASIZE;
  hspi2.Init.NSSPMode = SPI_NSS_PULSE_ENABLE;
  if (HAL_SPI_Init(&hspi2) != HAL_OK)
  {
    Error_Handler();
  }

}

static void MX_TIM2_Init(void)
{

  TIM_MasterConfigTypeDef sMasterConfig = {0};
  TIM_OC_InitTypeDef sConfigOC = {0};

  htim2.Instance = TIM2;
  htim2.Init.Prescaler = 0;
  htim2.Init.CounterMode = TIM_COUNTERMODE_UP;
  htim2.Init.Period = 4294967295;
  htim2.Init.ClockDivision = TIM_CLOCKDIVISION_DIV1;
  htim2.Init.AutoReloadPreload = TIM_AUTORELOAD_PRELOAD_DISABLE;
  if (HAL_TIM_PWM_Init(&htim2) != HAL_OK)
  {
    Error_Handler();
  }
  sMasterConfig.MasterOutputTrigger = TIM_TRGO_RESET;
  sMasterConfig.MasterSlaveMode = TIM_MASTERSLAVEMODE_DISABLE;
  if (HAL_TIMEx_MasterConfigSynchronization(&htim2, &sMasterConfig) != HAL_OK)
  {
    Error_Handler();
  }
  sConfigOC.OCMode = TIM_OCMODE_PWM1;
  sConfigOC.Pulse = 0;
  sConfigOC.OCPolarity = TIM_OCPOLARITY_HIGH;
  sConfigOC.OCFastMode = TIM_OCFAST_DISABLE;
  if (HAL_TIM_PWM_ConfigChannel(&htim2, &sConfigOC, TIM_CHANNEL_1) != HAL_OK)
  {
    Error_Handler();
  }
  HAL_TIM_MspPostInit(&htim2);

}

static void MX_TIM3_Init(void)
{

  TIM_MasterConfigTypeDef sMasterConfig = {0};
  TIM_OC_InitTypeDef sConfigOC = {0};

  htim3.Instance = TIM3;
  htim3.Init.Prescaler = 0;
  htim3.Init.CounterMode = TIM_COUNTERMODE_UP;
  htim3.Init.Period = 65535;
  htim3.Init.ClockDivision = TIM_CLOCKDIVISION_DIV1;
  htim3.Init.AutoReloadPreload = TIM_AUTORELOAD_PRELOAD_DISABLE;
  if (HAL_TIM_PWM_Init(&htim3) != HAL_OK)
  {
    Error_Handler();
  }
  sMasterConfig.MasterOutputTrigger = TIM_TRGO_RESET;
  sMasterConfig.MasterSlaveMode = TIM_MASTERSLAVEMODE_DISABLE;
  if (HAL_TIMEx_MasterConfigSynchronization(&htim3, &sMasterConfig) != HAL_OK)
  {
    Error_Handler();
  }
  sConfigOC.OCMode = TIM_OCMODE_PWM1;
  sConfigOC.Pulse = 0;
  sConfigOC.OCPolarity = TIM_OCPOLARITY_HIGH;
  sConfigOC.OCFastMode = TIM_OCFAST_DISABLE;
  if (HAL_TIM_PWM_ConfigChannel(&htim3, &sConfigOC, TIM_CHANNEL_3) != HAL_OK)
  {
    Error_Handler();
  }
  HAL_TIM_MspPostInit(&htim3);

}

static void MX_TIM5_Init(void)
{

  TIM_ClockConfigTypeDef sClockSourceConfig = {0};
  TIM_MasterConfigTypeDef sMasterConfig = {0};

  htim5.Instance = TIM5;
  htim5.Init.Prescaler = 0;
  htim5.Init.CounterMode = TIM_COUNTERMODE_UP;
  htim5.Init.Period = 216000;
  htim5.Init.ClockDivision = TIM_CLOCKDIVISION_DIV1;
  htim5.Init.AutoReloadPreload = TIM_AUTORELOAD_PRELOAD_DISABLE;
  if (HAL_TIM_Base_Init(&htim5) != HAL_OK)
  {
    Error_Handler();
  }
  sClockSourceConfig.ClockSource = TIM_CLOCKSOURCE_INTERNAL;
  if (HAL_TIM_ConfigClockSource(&htim5, &sClockSourceConfig) != HAL_OK)
  {
    Error_Handler();
  }
  sMasterConfig.MasterOutputTrigger = TIM_TRGO_UPDATE;
  sMasterConfig.MasterSlaveMode = TIM_MASTERSLAVEMODE_DISABLE;
  if (HAL_TIMEx_MasterConfigSynchronization(&htim5, &sMasterConfig) != HAL_OK)
  {
    Error_Handler();
  }

}

static void MX_TIM9_Init(void)
{

  TIM_OC_InitTypeDef sConfigOC = {0};

  htim9.Instance = TIM9;
  htim9.Init.Prescaler = 0;
  htim9.Init.CounterMode = TIM_COUNTERMODE_UP;
  htim9.Init.Period = 65535;
  htim9.Init.ClockDivision = TIM_CLOCKDIVISION_DIV1;
  htim9.Init.AutoReloadPreload = TIM_AUTORELOAD_PRELOAD_DISABLE;
  if (HAL_TIM_PWM_Init(&htim9) != HAL_OK)
  {
    Error_Handler();
  }
  sConfigOC.OCMode = TIM_OCMODE_PWM1;
  sConfigOC.Pulse = 0;
  sConfigOC.OCPolarity = TIM_OCPOLARITY_HIGH;
  sConfigOC.OCFastMode = TIM_OCFAST_DISABLE;
  if (HAL_TIM_PWM_ConfigChannel(&htim9, &sConfigOC, TIM_CHANNEL_1) != HAL_OK)
  {
    Error_Handler();
  }
  if (HAL_TIM_PWM_ConfigChannel(&htim9, &sConfigOC, TIM_CHANNEL_2) != HAL_OK)
  {
    Error_Handler();
  }
  HAL_TIM_MspPostInit(&htim9);

}

static void MX_TIM12_Init(void)
{

  TIM_OC_InitTypeDef sConfigOC = {0};

  htim12.Instance = TIM12;
  htim12.Init.Prescaler = 0;
  htim12.Init.CounterMode = TIM_COUNTERMODE_UP;
  htim12.Init.Period = 65535;
  htim12.Init.ClockDivision = TIM_CLOCKDIVISION_DIV1;
  htim12.Init.AutoReloadPreload = TIM_AUTORELOAD_PRELOAD_DISABLE;
  if (HAL_TIM_PWM_Init(&htim12) != HAL_OK)
  {
    Error_Handler();
  }
  sConfigOC.OCMode = TIM_OCMODE_PWM1;
  sConfigOC.Pulse = 0;
  sConfigOC.OCPolarity = TIM_OCPOLARITY_HIGH;
  sConfigOC.OCFastMode = TIM_OCFAST_DISABLE;
  if (HAL_TIM_PWM_ConfigChannel(&htim12, &sConfigOC, TIM_CHANNEL_1) != HAL_OK)
  {
    Error_Handler();
  }
  HAL_TIM_MspPostInit(&htim12);

}

static void MX_UART4_Init(void)
{

  huart4.Instance = UART4;
  huart4.Init.BaudRate = 115200;
  huart4.Init.WordLength = UART_WORDLENGTH_8B;
  huart4.Init.StopBits = UART_STOPBITS_1;
  huart4.Init.Parity = UART_PARITY_NONE;
  huart4.Init.Mode = UART_MODE_TX_RX;
  huart4.Init.HwFlowCtl = UART_HWCONTROL_NONE;
  huart4.Init.OverSampling = UART_OVERSAMPLING_16;
  huart4.Init.OneBitSampling = UART_ONE_BIT_SAMPLE_DISABLE;
  huart4.AdvancedInit.AdvFeatureInit = UART_ADVFEATURE_NO_INIT;
  if (HAL_UART_Init(&huart4) != HAL_OK)
  {
    Error_Handler();
  }

}

static void MX_UART5_Init(void)
{

  huart5.Instance = UART5;
  huart5.Init.BaudRate = 115200;
  huart5.Init.WordLength = UART_WORDLENGTH_8B;
  huart5.Init.StopBits = UART_STOPBITS_1;
  huart5.Init.Parity = UART_PARITY_NONE;
  huart5.Init.Mode = UART_MODE_TX_RX;
  huart5.Init.HwFlowCtl = UART_HWCONTROL_NONE;
  huart5.Init.OverSampling = UART_OVERSAMPLING_16;
  huart5.Init.OneBitSampling = UART_ONE_BIT_SAMPLE_DISABLE;
  huart5.AdvancedInit.AdvFeatureInit = UART_ADVFEATURE_NO_INIT;
  if (HAL_UART_Init(&huart5) != HAL_OK)
  {
    Error_Handler();
  }

}

static void MX_UART7_Init(void)
{

  huart7.Instance = UART7;
  huart7.Init.BaudRate = 115200;
  huart7.Init.WordLength = UART_WORDLENGTH_8B;
  huart7.Init.StopBits = UART_STOPBITS_1;
  huart7.Init.Parity = UART_PARITY_NONE;
  huart7.Init.Mode = UART_MODE_TX_RX;
  huart7.Init.HwFlowCtl = UART_HWCONTROL_RTS_CTS;
  huart7.Init.OverSampling = UART_OVERSAMPLING_16;
  huart7.Init.OneBitSampling = UART_ONE_BIT_SAMPLE_DISABLE;
  huart7.AdvancedInit.AdvFeatureInit = UART_ADVFEATURE_NO_INIT;
  if (HAL_UART_Init(&huart7) != HAL_OK)
  {
    Error_Handler();
  }

}

static void MX_USART2_UART_Init(void)
{

  huart2.Instance = USART2;
  huart2.Init.BaudRate = 115200;
  huart2.Init.WordLength = UART_WORDLENGTH_8B;
  huart2.Init.StopBits = UART_STOPBITS_1;
  huart2.Init.Parity = UART_PARITY_NONE;
  huart2.Init.Mode = UART_MODE_TX_RX;
  huart2.Init.HwFlowCtl = UART_HWCONTROL_NONE;
  huart2.Init.OverSampling = UART_OVERSAMPLING_16;
  huart2.Init.OneBitSampling = UART_ONE_BIT_SAMPLE_DISABLE;
  huart2.AdvancedInit.AdvFeatureInit = UART_ADVFEATURE_NO_INIT;
  if (HAL_UART_Init(&huart2) != HAL_OK)
  {
    Error_Handler();
  }

}

static void MX_USART6_UART_Init(void)
{

  huart6.Instance = USART6;
  huart6.Init.BaudRate = 115200;
  huart6.Init.WordLength = UART_WORDLENGTH_8B;
  huart6.Init.StopBits = UART_STOPBITS_1;
  huart6.Init.Parity = UART_PARITY_NONE;
  huart6.Init.Mode = UART_MODE_TX_RX;
  huart6.Init.HwFlowCtl = UART_HWCONTROL_NONE;
  huart6.Init.OverSampling = UART_OVERSAMPLING_16;
  huart6.Init.OneBitSampling = UART_ONE_BIT_SAMPLE_DISABLE;
  huart6.AdvancedInit.AdvFeatureInit = UART_ADVFEATURE_NO_INIT;
  if (HAL_UART_Init(&huart6) != HAL_OK)
  {
    Error_Handler();
  }

}

/* FMC initialization function */
static void MX_FMC_Init(void)
{

  FMC_NORSRAM_TimingTypeDef Timing = {0};

  /** Perform the SRAM1 memory initialization sequence
  */
  hsram1.Instance = FMC_NORSRAM_DEVICE;
  hsram1.Extended = FMC_NORSRAM_EXTENDED_DEVICE;
  /* hsram1.Init */
  hsram1.Init.NSBank = FMC_NORSRAM_BANK1;
  hsram1.Init.DataAddressMux = FMC_DATA_ADDRESS_MUX_DISABLE;
  hsram1.Init.MemoryType = FMC_MEMORY_TYPE_PSRAM;
  hsram1.Init.MemoryDataWidth = FMC_NORSRAM_MEM_BUS_WIDTH_16;
  hsram1.Init.BurstAccessMode = FMC_BURST_ACCESS_MODE_DISABLE;
  hsram1.Init.WaitSignalPolarity = FMC_WAIT_SIGNAL_POLARITY_LOW;
  hsram1.Init.WaitSignalActive = FMC_WAIT_TIMING_BEFORE_WS;
  hsram1.Init.WriteOperation = FMC_WRITE_OPERATION_ENABLE;
  hsram1.Init.WaitSignal = FMC_WAIT_SIGNAL_DISABLE;
  hsram1.Init.ExtendedMode = FMC_EXTENDED_MODE_DISABLE;
  hsram1.Init.AsynchronousWait = FMC_ASYNCHRONOUS_WAIT_DISABLE;
  hsram1.Init.WriteBurst = FMC_WRITE_BURST_DISABLE;
  hsram1.Init.ContinuousClock = FMC_CONTINUOUS_CLOCK_SYNC_ONLY;
  hsram1.Init.WriteFifo = FMC_WRITE_FIFO_ENABLE;
  hsram1.Init.PageSize = FMC_PAGE_SIZE_NONE;
  /* Timing */
  Timing.AddressSetupTime = 15;
  Timing.AddressHoldTime = 15;
  Timing.DataSetupTime = 255;
  Timing.BusTurnAroundDuration = 15;
  Timing.CLKDivision = 16;
  Timing.DataLatency = 17;
  Timing.AccessMode = FMC_ACCESS_MODE_A;
  /* ExtTiming */

  if (HAL_SRAM_Init(&hsram1, &Timing, NULL) != HAL_OK)
  {
    Error_Handler( );
  }

  /** Perform the SRAM2 memory initialization sequence
  */
  hsram2.Instance = FMC_NORSRAM_DEVICE;
  hsram2.Extended = FMC_NORSRAM_EXTENDED_DEVICE;
  /* hsram2.Init */
  hsram2.Init.NSBank = FMC_NORSRAM_BANK2;
  hsram2.Init.DataAddressMux = FMC_DATA_ADDRESS_MUX_DISABLE;
  hsram2.Init.MemoryType = FMC_MEMORY_TYPE_SRAM;
  hsram2.Init.MemoryDataWidth = FMC_NORSRAM_MEM_BUS_WIDTH_16;
  hsram2.Init.BurstAccessMode = FMC_BURST_ACCESS_MODE_DISABLE;
  hsram2.Init.WaitSignalPolarity = FMC_WAIT_SIGNAL_POLARITY_LOW;
  hsram2.Init.WaitSignalActive = FMC_WAIT_TIMING_BEFORE_WS;
  hsram2.Init.WriteOperation = FMC_WRITE_OPERATION_ENABLE;
  hsram2.Init.WaitSignal = FMC_WAIT_SIGNAL_DISABLE;
  hsram2.Init.ExtendedMode = FMC_EXTENDED_MODE_DISABLE;
  hsram2.Init.AsynchronousWait = FMC_ASYNCHRONOUS_WAIT_DISABLE;
  hsram2.Init.WriteBurst = FMC_WRITE_BURST_DISABLE;
  hsram2.Init.ContinuousClock = FMC_CONTINUOUS_CLOCK_SYNC_ONLY;
  hsram2.Init.WriteFifo = FMC_WRITE_FIFO_ENABLE;
  hsram2.Init.PageSize = FMC_PAGE_SIZE_NONE;
  /* Timing */
  Timing.AddressSetupTime = 15;
  Timing.AddressHoldTime = 15;
  Timing.DataSetupTime = 255;
  Timing.BusTurnAroundDuration = 15;
  Timing.CLKDivision = 16;
  Timing.DataLatency = 17;
  Timing.AccessMode = FMC_ACCESS_MODE_A;
  /* ExtTiming */

  if (HAL_SRAM_Init(&hsram2, &Timing, NULL) != HAL_OK)
  {
    Error_Handler( );
  }

}

static void MX_GPIO_Init(void)
{
  GPIO_InitTypeDef GPIO_InitStruct = {0};

  /* GPIO Ports Clock Enable */
  __HAL_RCC_GPIOE_CLK_ENABLE();
  __HAL_RCC_GPIOB_CLK_ENABLE();
  __HAL_RCC_GPIOG_CLK_ENABLE();
  __HAL_RCC_GPIOD_CLK_ENABLE();
  __HAL_RCC_GPIOC_CLK_ENABLE();
  __HAL_RCC_GPIOA_CLK_ENABLE();
  __HAL_RCC_GPIOI_CLK_ENABLE();
  __HAL_RCC_GPIOH_CLK_ENABLE();
  __HAL_RCC_GPIOF_CLK_ENABLE();

  /*Configure GPIO pin Output Level */
  HAL_GPIO_WritePin(GPIOE, ARD_D7_GPIO_Pin|GPIO_PIN_4, GPIO_PIN_RESET);

  /*Configure GPIO pin Output Level */
  HAL_GPIO_WritePin(GPIOG, WIFI_RST_Pin|WIFI_GPIO_0_Pin|PMOD_GPIO_0_Pin|USB_OTGFS_PPWR_EN_Pin, GPIO_PIN_RESET);

  /*Configure GPIO pin Output Level */
  HAL_GPIO_WritePin(GPIOD, WIFI_GPIO_2_Pin|WIFI_CH_PD_Pin, GPIO_PIN_RESET);

  /*Configure GPIO pin Output Level */
  HAL_GPIO_WritePin(GPIOC, STMOD_UART4_RXD_s_Pin|ARD_D2_GPIO_Pin, GPIO_PIN_RESET);

  /*Configure GPIO pin Output Level */
  HAL_GPIO_WritePin(GPIOI, PMOD_SPI2_MOSI_Pin|PMOD_SPI2_MISO_Pin|GPIO_PIN_10, GPIO_PIN_RESET);

  /*Configure GPIO pin Output Level */
  HAL_GPIO_WritePin(PMOD_SEL_0_GPIO_Port, PMOD_SEL_0_Pin, GPIO_PIN_SET);

  /*Configure GPIO pin Output Level */
  HAL_GPIO_WritePin(GPIOA, USB_OTG_FS_ID_Pin|SYS_LD_USER1_Pin, GPIO_PIN_RESET);

  /*Configure GPIO pin Output Level */
  HAL_GPIO_WritePin(GPIOH, PMOD_GPIO_1_Pin|ARD_D4_GPIO_Pin|USB_OTGHS_PPWR_EN_Pin|CTP_RST_Pin
                          |LCD_RST_Pin, GPIO_PIN_RESET);

  /*Configure GPIO pin Output Level */
  HAL_GPIO_WritePin(GPIOB, USB_OTG_HS_ID_Pin|SYS_LD_USER2_Pin, GPIO_PIN_RESET);

  /*Configure GPIO pins : ARD_D7_GPIO_Pin PE4 */
  GPIO_InitStruct.Pin = ARD_D7_GPIO_Pin|GPIO_PIN_4;
  GPIO_InitStruct.Mode = GPIO_MODE_OUTPUT_PP;
  GPIO_InitStruct.Pull = GPIO_NOPULL;
  GPIO_InitStruct.Speed = GPIO_SPEED_FREQ_LOW;
  HAL_GPIO_Init(GPIOE, &GPIO_InitStruct);

  /*Configure GPIO pins : WIFI_RST_Pin WIFI_GPIO_0_Pin PMOD_GPIO_0_Pin USB_OTGFS_PPWR_EN_Pin */
  GPIO_InitStruct.Pin = WIFI_RST_Pin|WIFI_GPIO_0_Pin|PMOD_GPIO_0_Pin|USB_OTGFS_PPWR_EN_Pin;
  GPIO_InitStruct.Mode = GPIO_MODE_OUTPUT_PP;
  GPIO_InitStruct.Pull = GPIO_NOPULL;
  GPIO_InitStruct.Speed = GPIO_SPEED_FREQ_LOW;
  HAL_GPIO_Init(GPIOG, &GPIO_InitStruct);

  /*Configure GPIO pin : SAI2_INT_Pin */
  GPIO_InitStruct.Pin = SAI2_INT_Pin;
  GPIO_InitStruct.Mode = GPIO_MODE_IT_RISING;
  GPIO_InitStruct.Pull = GPIO_NOPULL;
  HAL_GPIO_Init(SAI2_INT_GPIO_Port, &GPIO_InitStruct);

  /*Configure GPIO pins : WIFI_GPIO_2_Pin WIFI_CH_PD_Pin */
  GPIO_InitStruct.Pin = WIFI_GPIO_2_Pin|WIFI_CH_PD_Pin;
  GPIO_InitStruct.Mode = GPIO_MODE_OUTPUT_PP;
  GPIO_InitStruct.Pull = GPIO_NOPULL;
  GPIO_InitStruct.Speed = GPIO_SPEED_FREQ_LOW;
  HAL_GPIO_Init(GPIOD, &GPIO_InitStruct);

  /*Configure GPIO pins : STMOD_UART4_RXD_s_Pin ARD_D2_GPIO_Pin */
  GPIO_InitStruct.Pin = STMOD_UART4_RXD_s_Pin|ARD_D2_GPIO_Pin;
  GPIO_InitStruct.Mode = GPIO_MODE_OUTPUT_PP;
  GPIO_InitStruct.Pull = GPIO_NOPULL;
  GPIO_InitStruct.Speed = GPIO_SPEED_FREQ_LOW;
  HAL_GPIO_Init(GPIOC, &GPIO_InitStruct);

  /*Configure GPIO pins : PMOD_SPI2_MOSI_Pin PMOD_SPI2_MISO_Pin PI10 */
  GPIO_InitStruct.Pin = PMOD_SPI2_MOSI_Pin|PMOD_SPI2_MISO_Pin|GPIO_PIN_10;
  GPIO_InitStruct.Mode = GPIO_MODE_OUTPUT_PP;
  GPIO_InitStruct.Pull = GPIO_NOPULL;
  GPIO_InitStruct.Speed = GPIO_SPEED_FREQ_LOW;
  HAL_GPIO_Init(GPIOI, &GPIO_InitStruct);

  /*Configure GPIO pin : CTP_INT_Pin */
  GPIO_InitStruct.Pin = CTP_INT_Pin;
  GPIO_InitStruct.Mode = GPIO_MODE_IT_RISING;
  GPIO_InitStruct.Pull = GPIO_NOPULL;
  HAL_GPIO_Init(CTP_INT_GPIO_Port, &GPIO_InitStruct);

  /*Configure GPIO pins : PMOD_SEL_0_Pin PMOD_GPIO_1_Pin ARD_D4_GPIO_Pin USB_OTGHS_PPWR_EN_Pin
                           CTP_RST_Pin LCD_RST_Pin */
  GPIO_InitStruct.Pin = PMOD_SEL_0_Pin|PMOD_GPIO_1_Pin|ARD_D4_GPIO_Pin|USB_OTGHS_PPWR_EN_Pin
                          |CTP_RST_Pin|LCD_RST_Pin;
  GPIO_InitStruct.Mode = GPIO_MODE_OUTPUT_PP;
  GPIO_InitStruct.Pull = GPIO_NOPULL;
  GPIO_InitStruct.Speed = GPIO_SPEED_FREQ_LOW;
  HAL_GPIO_Init(GPIOH, &GPIO_InitStruct);

  /*Configure GPIO pins : USB_OTG_FS_ID_Pin SYS_LD_USER1_Pin */
  GPIO_InitStruct.Pin = USB_OTG_FS_ID_Pin|SYS_LD_USER1_Pin;
  GPIO_InitStruct.Mode = GPIO_MODE_OUTPUT_PP;
  GPIO_InitStruct.Pull = GPIO_NOPULL;
  GPIO_InitStruct.Speed = GPIO_SPEED_FREQ_LOW;
  HAL_GPIO_Init(GPIOA, &GPIO_InitStruct);

  /*Configure GPIO pin : LCD_TE_INT_Pin */
  GPIO_InitStruct.Pin = LCD_TE_INT_Pin;
  GPIO_InitStruct.Mode = GPIO_MODE_IT_RISING;
  GPIO_InitStruct.Pull = GPIO_NOPULL;
  HAL_GPIO_Init(LCD_TE_INT_GPIO_Port, &GPIO_InitStruct);

  /*Configure GPIO pin : USB_OTGHS_OVCR_INT_Pin */
  GPIO_InitStruct.Pin = USB_OTGHS_OVCR_INT_Pin;
  GPIO_InitStruct.Mode = GPIO_MODE_INPUT;
  GPIO_InitStruct.Pull = GPIO_NOPULL;
  HAL_GPIO_Init(USB_OTGHS_OVCR_INT_GPIO_Port, &GPIO_InitStruct);

  /*Configure GPIO pins : USB_OTG_HS_ID_Pin SYS_LD_USER2_Pin */
  GPIO_InitStruct.Pin = USB_OTG_HS_ID_Pin|SYS_LD_USER2_Pin;
  GPIO_InitStruct.Mode = GPIO_MODE_OUTPUT_PP;
  GPIO_InitStruct.Pull = GPIO_NOPULL;
  GPIO_InitStruct.Speed = GPIO_SPEED_FREQ_LOW;
  HAL_GPIO_Init(GPIOB, &GPIO_InitStruct);

  /*Configure GPIO pins : USB_OTG_HS_VBUS_Pin USB_OTGFS_OVCR_INT_Pin PMOD_INT_Pin */
  GPIO_InitStruct.Pin = USB_OTG_HS_VBUS_Pin|USB_OTGFS_OVCR_INT_Pin|PMOD_INT_Pin;
  GPIO_InitStruct.Mode = GPIO_MODE_IT_RISING;
  GPIO_InitStruct.Pull = GPIO_NOPULL;
  HAL_GPIO_Init(GPIOB, &GPIO_InitStruct);

  /*Configure GPIO pin : PMOD_RESET_Pin */
  GPIO_InitStruct.Pin = PMOD_RESET_Pin;
  GPIO_InitStruct.Mode = GPIO_MODE_INPUT;
  GPIO_InitStruct.Pull = GPIO_NOPULL;
  HAL_GPIO_Init(PMOD_RESET_GPIO_Port, &GPIO_InitStruct);

}

void HAL_TIM_PeriodElapsedCallback(TIM_HandleTypeDef *htim)
{
  if (htim->Instance == TIM1) {
    HAL_IncTick();
  }
}

void Error_Handler(void)
{
  __disable_irq();
  while (1)
  {
  }
}
